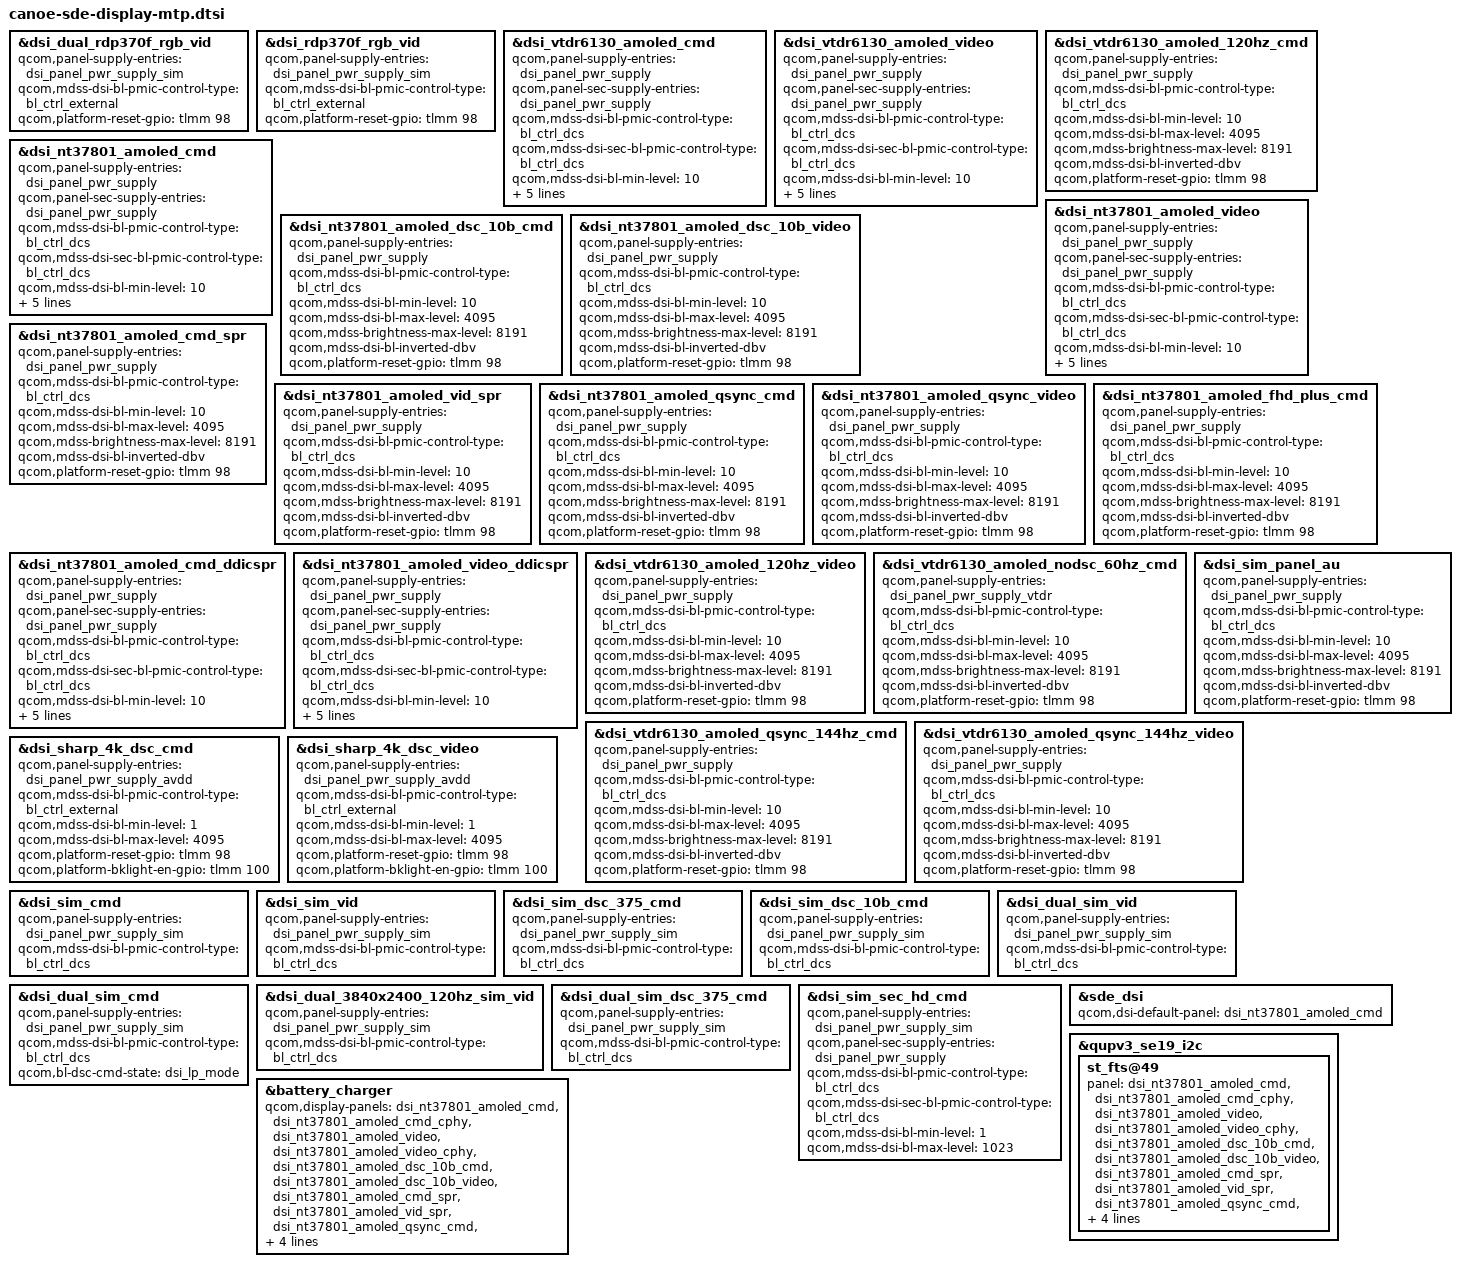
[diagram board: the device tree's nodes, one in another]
// SPDX-License-Identifier: BSD-3-Clause
/*
 * Copyright (c) Qualcomm Technologies, Inc. and/or its subsidiaries.
 */

#include "canoe-sde-display.dtsi"
#include "canoe-sde-display-hfi.dtsi"

&dsi_dual_rdp370f_rgb_vid {
	qcom,panel-supply-entries = <&dsi_panel_pwr_supply_sim>;
	qcom,mdss-dsi-bl-pmic-control-type = "bl_ctrl_external";
	qcom,platform-reset-gpio = <&tlmm 98 0>;
};

&dsi_rdp370f_rgb_vid {
	qcom,panel-supply-entries = <&dsi_panel_pwr_supply_sim>;
	qcom,mdss-dsi-bl-pmic-control-type = "bl_ctrl_external";
	qcom,platform-reset-gpio = <&tlmm 98 0>;
};

&dsi_vtdr6130_amoled_cmd {
	qcom,panel-supply-entries = <&dsi_panel_pwr_supply>;
	qcom,panel-sec-supply-entries = <&dsi_panel_pwr_supply>;
	qcom,mdss-dsi-bl-pmic-control-type = "bl_ctrl_dcs";
	qcom,mdss-dsi-sec-bl-pmic-control-type = "bl_ctrl_dcs";
	qcom,mdss-dsi-bl-min-level = <10>;
	qcom,mdss-dsi-bl-max-level = <4095>;
	qcom,mdss-brightness-max-level = <8191>;
	qcom,mdss-dsi-bl-inverted-dbv;
	qcom,platform-reset-gpio = <&tlmm 98 0>;
	qcom,platform-sec-reset-gpio = <&tlmm 97 0>;
};

&dsi_vtdr6130_amoled_video {
	qcom,panel-supply-entries = <&dsi_panel_pwr_supply>;
	qcom,panel-sec-supply-entries = <&dsi_panel_pwr_supply>;
	qcom,mdss-dsi-bl-pmic-control-type = "bl_ctrl_dcs";
	qcom,mdss-dsi-sec-bl-pmic-control-type = "bl_ctrl_dcs";
	qcom,mdss-dsi-bl-min-level = <10>;
	qcom,mdss-dsi-bl-max-level = <4095>;
	qcom,mdss-brightness-max-level = <8191>;
	qcom,mdss-dsi-bl-inverted-dbv;
	qcom,platform-reset-gpio = <&tlmm 98 0>;
	qcom,platform-sec-reset-gpio = <&tlmm 97 0>;
};

&dsi_vtdr6130_amoled_120hz_cmd {
	qcom,panel-supply-entries = <&dsi_panel_pwr_supply>;
	qcom,mdss-dsi-bl-pmic-control-type = "bl_ctrl_dcs";
	qcom,mdss-dsi-bl-min-level = <10>;
	qcom,mdss-dsi-bl-max-level = <4095>;
	qcom,mdss-brightness-max-level = <8191>;
	qcom,mdss-dsi-bl-inverted-dbv;
	qcom,platform-reset-gpio = <&tlmm 98 0>;
};

&dsi_nt37801_amoled_cmd {
	qcom,panel-supply-entries = <&dsi_panel_pwr_supply>;
	qcom,panel-sec-supply-entries = <&dsi_panel_pwr_supply>;
	qcom,mdss-dsi-bl-pmic-control-type = "bl_ctrl_dcs";
	qcom,mdss-dsi-sec-bl-pmic-control-type = "bl_ctrl_dcs";
	qcom,mdss-dsi-bl-min-level = <10>;
	qcom,mdss-dsi-bl-max-level = <4095>;
	qcom,mdss-brightness-max-level = <8191>;
	qcom,mdss-dsi-bl-inverted-dbv;
	qcom,platform-reset-gpio = <&tlmm 98 0>;
	qcom,platform-sec-reset-gpio = <&tlmm 97 0>;
};

&dsi_nt37801_amoled_video {
	qcom,panel-supply-entries = <&dsi_panel_pwr_supply>;
	qcom,panel-sec-supply-entries = <&dsi_panel_pwr_supply>;
	qcom,mdss-dsi-bl-pmic-control-type = "bl_ctrl_dcs";
	qcom,mdss-dsi-sec-bl-pmic-control-type = "bl_ctrl_dcs";
	qcom,mdss-dsi-bl-min-level = <10>;
	qcom,mdss-dsi-bl-max-level = <4095>;
	qcom,mdss-brightness-max-level = <8191>;
	qcom,mdss-dsi-bl-inverted-dbv;
	qcom,platform-reset-gpio = <&tlmm 98 0>;
	qcom,platform-sec-reset-gpio = <&tlmm 97 0>;
};

&dsi_nt37801_amoled_dsc_10b_cmd {
	qcom,panel-supply-entries = <&dsi_panel_pwr_supply>;
	qcom,mdss-dsi-bl-pmic-control-type = "bl_ctrl_dcs";
	qcom,mdss-dsi-bl-min-level = <10>;
	qcom,mdss-dsi-bl-max-level = <4095>;
	qcom,mdss-brightness-max-level = <8191>;
	qcom,mdss-dsi-bl-inverted-dbv;
	qcom,platform-reset-gpio = <&tlmm 98 0>;
};

&dsi_nt37801_amoled_dsc_10b_video {
	qcom,panel-supply-entries = <&dsi_panel_pwr_supply>;
	qcom,mdss-dsi-bl-pmic-control-type = "bl_ctrl_dcs";
	qcom,mdss-dsi-bl-min-level = <10>;
	qcom,mdss-dsi-bl-max-level = <4095>;
	qcom,mdss-brightness-max-level = <8191>;
	qcom,mdss-dsi-bl-inverted-dbv;
	qcom,platform-reset-gpio = <&tlmm 98 0>;
};

&dsi_nt37801_amoled_cmd_spr {
	qcom,panel-supply-entries = <&dsi_panel_pwr_supply>;
	qcom,mdss-dsi-bl-pmic-control-type = "bl_ctrl_dcs";
	qcom,mdss-dsi-bl-min-level = <10>;
	qcom,mdss-dsi-bl-max-level = <4095>;
	qcom,mdss-brightness-max-level = <8191>;
	qcom,mdss-dsi-bl-inverted-dbv;
	qcom,platform-reset-gpio = <&tlmm 98 0>;
};

&dsi_nt37801_amoled_vid_spr {
	qcom,panel-supply-entries = <&dsi_panel_pwr_supply>;
	qcom,mdss-dsi-bl-pmic-control-type = "bl_ctrl_dcs";
	qcom,mdss-dsi-bl-min-level = <10>;
	qcom,mdss-dsi-bl-max-level = <4095>;
	qcom,mdss-brightness-max-level = <8191>;
	qcom,mdss-dsi-bl-inverted-dbv;
	qcom,platform-reset-gpio = <&tlmm 98 0>;
};

&dsi_nt37801_amoled_qsync_cmd {
	qcom,panel-supply-entries = <&dsi_panel_pwr_supply>;
	qcom,mdss-dsi-bl-pmic-control-type = "bl_ctrl_dcs";
	qcom,mdss-dsi-bl-min-level = <10>;
	qcom,mdss-dsi-bl-max-level = <4095>;
	qcom,mdss-brightness-max-level = <8191>;
	qcom,mdss-dsi-bl-inverted-dbv;
	qcom,platform-reset-gpio = <&tlmm 98 0>;
};

&dsi_nt37801_amoled_qsync_video {
	qcom,panel-supply-entries = <&dsi_panel_pwr_supply>;
	qcom,mdss-dsi-bl-pmic-control-type = "bl_ctrl_dcs";
	qcom,mdss-dsi-bl-min-level = <10>;
	qcom,mdss-dsi-bl-max-level = <4095>;
	qcom,mdss-brightness-max-level = <8191>;
	qcom,mdss-dsi-bl-inverted-dbv;
	qcom,platform-reset-gpio = <&tlmm 98 0>;
};

&dsi_nt37801_amoled_fhd_plus_cmd {
	qcom,panel-supply-entries = <&dsi_panel_pwr_supply>;
	qcom,mdss-dsi-bl-pmic-control-type = "bl_ctrl_dcs";
	qcom,mdss-dsi-bl-min-level = <10>;
	qcom,mdss-dsi-bl-max-level = <4095>;
	qcom,mdss-brightness-max-level = <8191>;
	qcom,mdss-dsi-bl-inverted-dbv;
	qcom,platform-reset-gpio = <&tlmm 98 0>;
};

&dsi_nt37801_amoled_cmd_ddicspr {
	qcom,panel-supply-entries = <&dsi_panel_pwr_supply>;
	qcom,panel-sec-supply-entries = <&dsi_panel_pwr_supply>;
	qcom,mdss-dsi-bl-pmic-control-type = "bl_ctrl_dcs";
	qcom,mdss-dsi-sec-bl-pmic-control-type = "bl_ctrl_dcs";
	qcom,mdss-dsi-bl-min-level = <10>;
	qcom,mdss-dsi-bl-max-level = <4095>;
	qcom,mdss-brightness-max-level = <8191>;
	qcom,mdss-dsi-bl-inverted-dbv;
	qcom,platform-reset-gpio = <&tlmm 98 0>;
	qcom,platform-sec-reset-gpio = <&tlmm 97 0>;
};

&dsi_nt37801_amoled_video_ddicspr {
	qcom,panel-supply-entries = <&dsi_panel_pwr_supply>;
	qcom,panel-sec-supply-entries = <&dsi_panel_pwr_supply>;
	qcom,mdss-dsi-bl-pmic-control-type = "bl_ctrl_dcs";
	qcom,mdss-dsi-sec-bl-pmic-control-type = "bl_ctrl_dcs";
	qcom,mdss-dsi-bl-min-level = <10>;
	qcom,mdss-dsi-bl-max-level = <4095>;
	qcom,mdss-brightness-max-level = <8191>;
	qcom,mdss-dsi-bl-inverted-dbv;
	qcom,platform-reset-gpio = <&tlmm 98 0>;
	qcom,platform-sec-reset-gpio = <&tlmm 97 0>;
};

&dsi_vtdr6130_amoled_120hz_video {
	qcom,panel-supply-entries = <&dsi_panel_pwr_supply>;
	qcom,mdss-dsi-bl-pmic-control-type = "bl_ctrl_dcs";
	qcom,mdss-dsi-bl-min-level = <10>;
	qcom,mdss-dsi-bl-max-level = <4095>;
	qcom,mdss-brightness-max-level = <8191>;
	qcom,mdss-dsi-bl-inverted-dbv;
	qcom,platform-reset-gpio = <&tlmm 98 0>;
};

&dsi_vtdr6130_amoled_nodsc_60hz_cmd {
	qcom,panel-supply-entries = <&dsi_panel_pwr_supply_vtdr>;
	qcom,mdss-dsi-bl-pmic-control-type = "bl_ctrl_dcs";
	qcom,mdss-dsi-bl-min-level = <10>;
	qcom,mdss-dsi-bl-max-level = <4095>;
	qcom,mdss-brightness-max-level = <8191>;
	qcom,mdss-dsi-bl-inverted-dbv;
	qcom,platform-reset-gpio = <&tlmm 98 0>;
};

&dsi_sim_panel_au {
	qcom,panel-supply-entries = <&dsi_panel_pwr_supply>;
	qcom,mdss-dsi-bl-pmic-control-type = "bl_ctrl_dcs";
	qcom,mdss-dsi-bl-min-level = <10>;
	qcom,mdss-dsi-bl-max-level = <4095>;
	qcom,mdss-brightness-max-level = <8191>;
	qcom,mdss-dsi-bl-inverted-dbv;
	qcom,platform-reset-gpio = <&tlmm 98 0>;
};

&dsi_vtdr6130_amoled_qsync_144hz_cmd {
	qcom,panel-supply-entries = <&dsi_panel_pwr_supply>;
	qcom,mdss-dsi-bl-pmic-control-type = "bl_ctrl_dcs";
	qcom,mdss-dsi-bl-min-level = <10>;
	qcom,mdss-dsi-bl-max-level = <4095>;
	qcom,mdss-brightness-max-level = <8191>;
	qcom,mdss-dsi-bl-inverted-dbv;
	qcom,platform-reset-gpio = <&tlmm 98 0>;
};

&dsi_vtdr6130_amoled_qsync_144hz_video {
	qcom,panel-supply-entries = <&dsi_panel_pwr_supply>;
	qcom,mdss-dsi-bl-pmic-control-type = "bl_ctrl_dcs";
	qcom,mdss-dsi-bl-min-level = <10>;
	qcom,mdss-dsi-bl-max-level = <4095>;
	qcom,mdss-brightness-max-level = <8191>;
	qcom,mdss-dsi-bl-inverted-dbv;
	qcom,platform-reset-gpio = <&tlmm 98 0>;
};

&dsi_sharp_4k_dsc_cmd {
	qcom,panel-supply-entries = <&dsi_panel_pwr_supply_avdd>;
	qcom,mdss-dsi-bl-pmic-control-type = "bl_ctrl_external";
	qcom,mdss-dsi-bl-min-level = <1>;
	qcom,mdss-dsi-bl-max-level = <4095>;
	qcom,platform-reset-gpio = <&tlmm 98 0>;
	qcom,platform-bklight-en-gpio = <&tlmm 100 0>;
};

&dsi_sharp_4k_dsc_video {
	qcom,panel-supply-entries = <&dsi_panel_pwr_supply_avdd>;
	qcom,mdss-dsi-bl-pmic-control-type = "bl_ctrl_external";
	qcom,mdss-dsi-bl-min-level = <1>;
	qcom,mdss-dsi-bl-max-level = <4095>;
	qcom,platform-reset-gpio = <&tlmm 98 0>;
	qcom,platform-bklight-en-gpio = <&tlmm 100 0>;
};

&dsi_sim_cmd {
	qcom,panel-supply-entries = <&dsi_panel_pwr_supply_sim>;
	qcom,mdss-dsi-bl-pmic-control-type = "bl_ctrl_dcs";
};

&dsi_sim_vid {
	qcom,panel-supply-entries = <&dsi_panel_pwr_supply_sim>;
	qcom,mdss-dsi-bl-pmic-control-type = "bl_ctrl_dcs";
};

&dsi_sim_dsc_375_cmd {
	qcom,panel-supply-entries = <&dsi_panel_pwr_supply_sim>;
	qcom,mdss-dsi-bl-pmic-control-type = "bl_ctrl_dcs";
};

&dsi_sim_dsc_10b_cmd {
	qcom,panel-supply-entries = <&dsi_panel_pwr_supply_sim>;
	qcom,mdss-dsi-bl-pmic-control-type = "bl_ctrl_dcs";
};

&dsi_dual_sim_vid {
	qcom,panel-supply-entries = <&dsi_panel_pwr_supply_sim>;
	qcom,mdss-dsi-bl-pmic-control-type = "bl_ctrl_dcs";
};

&dsi_dual_sim_cmd {
	qcom,panel-supply-entries = <&dsi_panel_pwr_supply_sim>;
	qcom,mdss-dsi-bl-pmic-control-type = "bl_ctrl_dcs";
	qcom,bl-dsc-cmd-state = "dsi_lp_mode";
};

&dsi_dual_3840x2400_120hz_sim_vid {
	qcom,panel-supply-entries = <&dsi_panel_pwr_supply_sim>;
	qcom,mdss-dsi-bl-pmic-control-type = "bl_ctrl_dcs";
};

&dsi_dual_sim_dsc_375_cmd {
	qcom,panel-supply-entries = <&dsi_panel_pwr_supply_sim>;
	qcom,mdss-dsi-bl-pmic-control-type = "bl_ctrl_dcs";
};

&dsi_sim_sec_hd_cmd {
	qcom,panel-supply-entries = <&dsi_panel_pwr_supply_sim>;
	qcom,panel-sec-supply-entries = <&dsi_panel_pwr_supply>;
	qcom,mdss-dsi-bl-pmic-control-type = "bl_ctrl_dcs";
	qcom,mdss-dsi-sec-bl-pmic-control-type = "bl_ctrl_dcs";
	qcom,mdss-dsi-bl-min-level = <1>;
	qcom,mdss-dsi-bl-max-level = <1023>;
};

&sde_dsi {
	qcom,dsi-default-panel = <&dsi_nt37801_amoled_cmd>;
};

&qupv3_se19_i2c {
	st_fts@49 {
		panel = <&dsi_nt37801_amoled_cmd
			&dsi_nt37801_amoled_cmd_cphy
			&dsi_nt37801_amoled_video
			&dsi_nt37801_amoled_video_cphy
			&dsi_nt37801_amoled_dsc_10b_cmd
			&dsi_nt37801_amoled_dsc_10b_video
			&dsi_nt37801_amoled_cmd_spr
			&dsi_nt37801_amoled_vid_spr
			&dsi_nt37801_amoled_qsync_cmd
			&dsi_nt37801_amoled_qsync_video
			&dsi_nt37801_amoled_fhd_plus_cmd
			&dsi_nt37801_amoled_cmd_ddicspr
			&dsi_nt37801_amoled_video_ddicspr>;
	};
};

&battery_charger {
	qcom,display-panels = <&dsi_nt37801_amoled_cmd
		&dsi_nt37801_amoled_cmd_cphy
		&dsi_nt37801_amoled_video
		&dsi_nt37801_amoled_video_cphy
		&dsi_nt37801_amoled_dsc_10b_cmd
		&dsi_nt37801_amoled_dsc_10b_video
		&dsi_nt37801_amoled_cmd_spr
		&dsi_nt37801_amoled_vid_spr
		&dsi_nt37801_amoled_qsync_cmd
		&dsi_nt37801_amoled_qsync_video
		&dsi_nt37801_amoled_fhd_plus_cmd
		&dsi_nt37801_amoled_cmd_ddicspr
		&dsi_nt37801_amoled_video_ddicspr>;
};
